# CM41x_M0 register map
Vendor: Analog Devices; Series: CM41x_M0; File version: 1p0
CPU: CM0 r0p0, little endian, MPU, FPU, 4 interrupt priority bits
Registers are 32-bit, read-write, reset 0x0 unless marked. A register's access mark holds for its fields unless they carry their own. Offsets are from the block's base; [hi:lo] are bit positions; lines under a group give offsets from that group; {n}, {i} and the like mark numbered series; 'fields as' and 'values as' point back to an identical list.

## CAN0 — Controller Area Network
Base 0x41008200
Same registers: CAN1 0x40024200
0x00 MC1 — Mailbox Configuration 1 Register
  [15:0] MB range 0x00000000..0x0000FFFF — Mailbox n Enable/Disable
0x04 MD1 reset 0xFF — Mailbox Direction 1 Register
  [15:8] MB range 0x00000000..0x000000FF — Mailbox n Transmit/Receive
0x08 TRS1 — Transmission Request Set 1 Register
  [15:8] MB range 0x00000000..0x000000FF — Mailbox n Transmit Request
0x0C TRR1 — Transmission Request Reset 1 Register
  [15:8] MB range 0x00000000..0x000000FF — Mailbox n Transmit Abort
0x10 TA1 — Transmission Acknowledge 1 Register
  [15:8] MB range 0x00000000..0x000000FF — Mailbox n Transmit Acknowledge
0x14 AA1 — Abort Acknowledge 1 Register
  [15:8] MB range 0x00000000..0x000000FF — Mailbox n Abort Acknowledge
0x18 RMP1 — Receive Message Pending 1 Register
  [15:0] MB range 0x00000000..0x0000FFFF — Mailbox n Message Pending
0x1C RML1 — Receive Message Lost 1 Register
  [15:0] MB ro — Mailbox n Message Lost
0x20 MBTIF1 — Mailbox Transmit Interrupt Flag 1 Register
  [15:8] MB range 0x00000000..0x000000FF — Mailbox n Transmit Interrupt Request Pending
0x24 MBRIF1 — Mailbox Receive Interrupt Flag 1 Register
  [15:0] MB range 0x00000000..0x0000FFFF — Mailbox n Receive Interrupt Request Pending
0x28 MBIM1 — Mailbox Interrupt Mask 1 Register
  [15:0] MB range 0x00000000..0x0000FFFF — Mailbox n Transmit and Receive Interrupt Request Enable
0x2C RFH1 — Remote Frame Handling 1 Register
  [15:8] MB range 0x00000000..0x000000FF — Mailbox n Remote Frame Handling Enable
0x30 OPSS1 — Overwrite Protection/Single Shot Transmission 1 Register
  [15:0] MB range 0x00000000..0x0000FFFF — Mailbox n Overwrite Protection Enable
0x40 MC2 — Mailbox Configuration 2 Register
  [15:0] MB range 0x00000000..0x0000FFFF — Mailbox n Enable/Disable
0x44 MD2 — Mailbox Direction 2 Register
  [7:0] MB range 0x00000000..0x000000FF — Mailbox n Transmit/Receive
0x48 TRS2 — Transmission Request Set 2 Register
  [15:0] MB range 0x00000000..0x0000FFFF — Mailbox n Transmit Request
0x4C TRR2 — Transmission Request Reset 2 Register
  [15:0] MB range 0x00000000..0x0000FFFF — Mailbox n Transmit Abort
0x50 TA2 — Transmission Acknowledge 2 Register
  [15:0] MB range 0x00000000..0x0000FFFF — Mailbox n Transmit Acknowledge
0x54 AA2 — Abort Acknowledge 2 Register
  [15:0] MB range 0x00000000..0x0000FFFF — Mailbox n Abort Acknowledge
0x58 RMP2 — Receive Message Pending 2 Register
  [7:0] MB range 0x00000000..0x000000FF — Mailbox n Message Pending
0x5C RML2 — Receive Message Lost 2 Register
  [7:0] MB ro — Mailbox n Message Lost
0x60 MBTIF2 — Mailbox Transmit Interrupt Flag 2 Register
  [15:0] MB range 0x00000000..0x0000FFFF — Mailbox n Transmit Interrupt Pending
0x64 MBRIF2 — Mailbox Receive Interrupt Flag 2 Register
  [7:0] MB range 0x00000000..0x000000FF — Mailbox n Receive Interrupt Pending
0x68 MBIM2 — Mailbox Interrupt Mask 2 Register
  [15:0] MB range 0x00000000..0x0000FFFF — Mailbox n Transmit and Receive Interrupt Enable
0x6C RFH2 — Remote Frame Handling 2 Register
  [7:0] MB range 0x00000000..0x000000FF — Mailbox n Remote Frame Handling Enable
0x70 OPSS2 — Overwrite Protection/Single Shot Transmission 2 Register
  fields as OPSS1
0x80 CLK — Clock Register
  [9:0] BRP range 0x00000000..0x000003FF — Bit Rate Prescaler
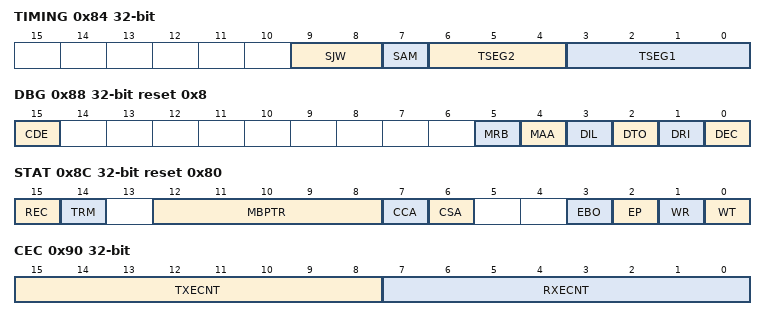
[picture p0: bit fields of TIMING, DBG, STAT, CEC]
0x84 TIMING
  [9:8] SJW range 0x00000000..0x00000003 — Synchronization Jump Width
  [7] SAM range 0x00000000..0x00000001 — Sampling
  [6:4] TSEG2 range 0x00000000..0x00000007 — Time Segment 2
  [3:0] TSEG1 range 0x00000000..0x0000000F — Time Segment 1
0x88 DBG reset 0x8 — Debug Register
  [15] CDE — CAN Debug Mode Enable
  [5] MRB — Mode Read Back
  [4] MAA — Mode Auto Acknowledge
  [3] DIL — Disable Internal Loop
  [2] DTO — Disable Tx Output Pin
  [1] DRI — Disable Receive Input Pin
  [0] DEC — Disable Transmit and Receive Error Counters
0x8C STAT reset 0x80 — Status Register
  [15] REC ro — Receive Mode
  [14] TRM ro — Transmit Mode
  [12:8] MBPTR ro — Mailbox Pointer
  [7] CCA ro — CAN Configuration Mode Acknowledge
  [6] CSA ro — CAN Suspend Mode Acknowledge
  [3] EBO ro — CAN Error Bus Off Mode
  [2] EP ro — CAN Error Passive Mode
  [1] WR ro — CAN Receive Warning Flag
  [0] WT ro — CAN Transmit Warning Flag
0x90 CEC — Error Counter Register
  [15:8] TXECNT range 0x00000000..0x000000FF — Transmit Error Counter
  [7:0] RXECNT range 0x00000000..0x000000FF — Receive Error Counter
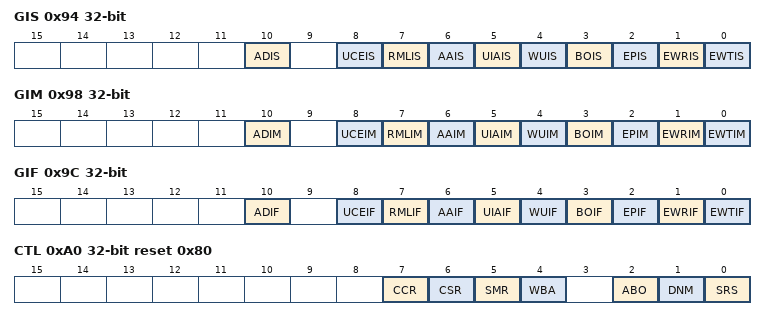
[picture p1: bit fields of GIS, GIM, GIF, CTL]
0x94 GIS — Global CAN Interrupt Status Register
  [10] ADIS — Access Denied Interrupt Status
  [8] UCEIS — Universal Counter Exceeded Interrupt Status
  [7] RMLIS — Receive Message Lost Interrupt Status
  [6] AAIS — Abort Acknowledge Interrupt Status
  [5] UIAIS — Unimplemented Address Interrupt Status
  [4] WUIS — Wake Up Interrupt Status
  [3] BOIS — Bus Off Interrupt Status
  [2] EPIS — Error Passive Interrupt Status
  [1] EWRIS — Error Warning Receive Interrupt Status
  [0] EWTIS — Error Warning Transmit Interrupt Status
0x98 GIM — Global CAN Interrupt Mask Register
  [10] ADIM — Access Denied Interrupt Mask
  [8] UCEIM — Universal Counter Exceeded Interrupt Mask
  [7] RMLIM — Receive Message Lost Interrupt Mask
  [6] AAIM — Abort Acknowledge Interrupt Mask
  [5] UIAIM — Unimplemented Address Interrupt Mask
  [4] WUIM — Wake Up Interrupt Mask
  [3] BOIM — Bus Off Interrupt Mask
  [2] EPIM — Error Passive Interrupt Mask
  [1] EWRIM — Error Warning Receive Interrupt Mask
  [0] EWTIM — Error Warning Transmit Interrupt Mask
0x9C GIF — Global CAN Interrupt Flag Register
  [10] ADIF ro — Access Denied Interrupt Flag
  [8] UCEIF ro — Universal Counter Exceeded Interrupt Flag
  [7] RMLIF ro — Receive Message Lost Interrupt Flag
  [6] AAIF ro — Abort Acknowledge Interrupt Flag
  [5] UIAIF ro — Unimplemented Address Interrupt Flag
  [4] WUIF ro — Wake Up Interrupt Flag
  [3] BOIF ro — Bus Off Interrupt Flag
  [2] EPIF ro — Error Passive Interrupt Flag
  [1] EWRIF ro — Error Warning Receive Interrupt Flag
  [0] EWTIF ro — Error Warning Transmit Interrupt Flag
0xA0 CTL reset 0x80 — CAN Master Control Register
  [7] CCR — CAN Configuration Mode Request
  [6] CSR — CAN Suspend Mode Request
  [5] SMR — Sleep Mode Request
  [4] WBA — Wake Up on CAN Bus Activity
  [2] ABO — Auto Bus On
  [1] DNM — Device Net Mode
  [0] SRS — Software Reset
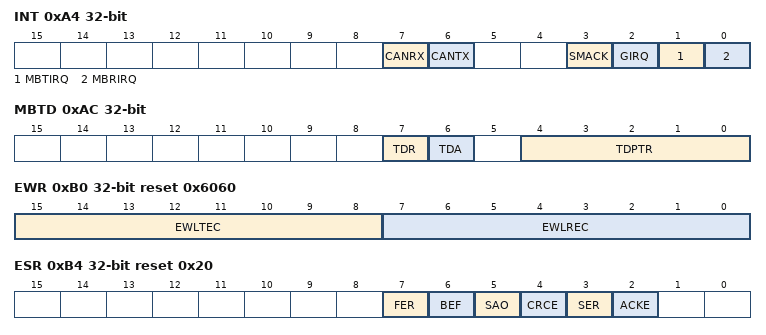
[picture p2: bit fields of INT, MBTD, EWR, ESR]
0xA4 INT — Interrupt Pending Register
  [7] CANRX ro — Serial Input From Transceiver
  [6] CANTX ro — Serial Input To Transceiver
  [3] SMACK — Sleep Mode Acknowledge
  [2] GIRQ — Global CAN Interrupt Output
  [1] MBTIRQ — Mailbox Transmit Interrupt Output
  [0] MBRIRQ — Mailbox Receive Interrupt Output
0xAC MBTD — Temporary Mailbox Disable Register
  [7] TDR — Temporary Disable Request
  [6] TDA ro — Temporary Disable Acknowledge
  [4:0] TDPTR range 0x00000000..0x0000001F — Temporary Disable Pointer
0xB0 EWR reset 0x6060 — Error Counter Warning Level Register
  [15:8] EWLTEC range 0x00000000..0x000000FF — Transmit Error Warning Limit
  [7:0] EWLREC range 0x00000000..0x000000FF — Receive Error Warning Limit
0xB4 ESR reset 0x20 — Error Status Register
  [7] FER — Form Error
  [6] BEF — Bit Error Flag
  [5] SAO — Stuck at Dominant
  [4] CRCE — CRC Error
  [3] SER — Stuff Bit Error
  [2] ACKE — Acknowledge Error
0xC4 UCCNT — Universal Counter Register
  [15:0] COUNT range 0x00000000..0x0000FFFF — Count Value
0xC8 UCRC — Universal Counter Reload/Capture Register
  [15:0] UCVAL range 0x00000000..0x0000FFFF — Universal Counter Value
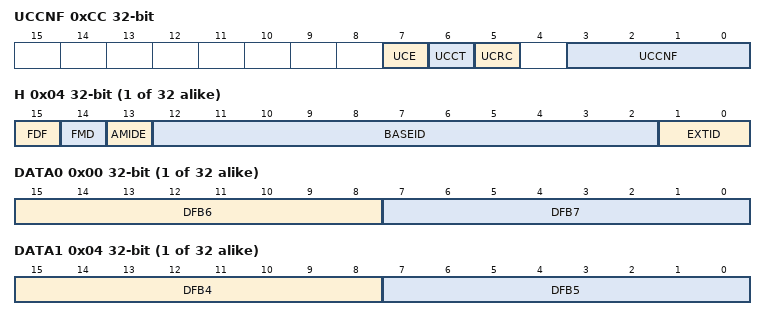
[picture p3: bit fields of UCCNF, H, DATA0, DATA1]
0xCC UCCNF — Universal Counter Configuration Mode Register
  [7] UCE — Universal Counter Enable
  [6] UCCT — Universal Counter CAN Trigger
  [5] UCRC — Universal Counter Reload/Clear
  [3:0] UCCNF — Universal Counter Configuration
{0x100+8i} AM[{i}] (i=0..31) group — Number of Acceptance Mask Registers
  0x00 L — Acceptance Mask (L) Register
    [15:0] EXTID range 0x00000000..0x0000FFFF — Extended Identifier/Data Field Mask
  0x04 H — Acceptance Mask (H) Register
    [15] FDF range 0x00000000..0x00000001 — Filter on Delay Field
    [14] FMD range 0x00000000..0x00000001 — Full Mask Data
    [13] AMIDE range 0x00000000..0x00000001 — Acceptance Mask Identifier Extension
    [12:2] BASEID range 0x00000000..0x000007FF — Base Identifier
    [1:0] EXTID range 0x00000000..0x00000003 — Extended Identifier
{0x200+0x20*i} MB[{i}] (i=0..31) group — Number of Mailbox Registers
  0x00 DATA0 — Mailbox Word 0 Register
    [15:8] DFB6 range 0x00000000..0x000000FF — Data Field Byte 6
    [7:0] DFB7 range 0x00000000..0x000000FF — Data Field Byte 7
  0x04 DATA1 — Mailbox Word 1 Register
    [15:8] DFB4 range 0x00000000..0x000000FF — Data Field Byte 4
    [7:0] DFB5 range 0x00000000..0x000000FF — Data Field Byte 5
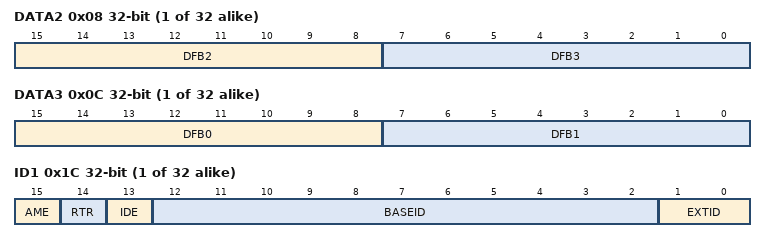
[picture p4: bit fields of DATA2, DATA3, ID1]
  0x08 DATA2 — Mailbox Word 2 Register
    [15:8] DFB2 range 0x00000000..0x000000FF — Data Field Byte 2
    [7:0] DFB3 range 0x00000000..0x000000FF — Data Field Byte 3
  0x0C DATA3 — Mailbox Word 3 Register
    [15:8] DFB0 range 0x00000000..0x000000FF — Data Field Byte 0
    [7:0] DFB1 range 0x00000000..0x000000FF — Data Field Byte 1
  0x10 LENGTH — Mailbox Length Register
    [3:0] DLC range 0x00000000..0x0000000F — Data Length Code
  0x14 TIMESTAMP — Mailbox Time Stamp Register
    [15:0] TSV range 0x00000000..0x0000FFFF — Time Stamp Value
  0x18 ID0 — Mailbox ID 0 Register
    [15:0] EXTID range 0x00000000..0x0000FFFF — Extended Identifier/Data Field Acceptance Code
  0x1C ID1 — Mailbox ID 1 Register
    [15] AME range 0x00000000..0x00000001 — Acceptance Mask Enable
    [14] RTR range 0x00000000..0x00000001 — Remote Transmission Request
    [13] IDE range 0x00000000..0x00000001 — Identifier Extension
    [12:2] BASEID range 0x00000000..0x000007FF — Base Identifier
    [1:0] EXTID range 0x00000000..0x00000003 — Extended Identifier
